AUTOSAR XML (schema 00050)
standard types defined: Boolean, Float
package /ARRoot
  swc implementation AntiPinchingSensorImpFile: programming-language=C, behavior=AntiPinchingSensorIB
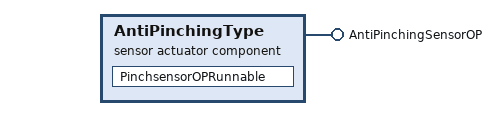
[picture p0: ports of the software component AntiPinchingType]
  sensor actuator sw component type AntiPinchingType
    provide port AntiPinchingSensorOP
    behavior AntiPinchingSensorIB
      runnable PinchsensorOPRunnable: external-triggering-point=AntiPinchingSensorOP.
  sender receiver interface PWControlSwitchSRIF: data-elements=variable-data-prototype=type=Boolean
  sender receiver interface PWMotorSRIF: data-elements=variable-data-prototype=type=Boolean
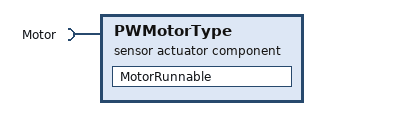
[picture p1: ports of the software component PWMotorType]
  sensor actuator sw component type PWMotorType
    require port Motor
    behavior MotorIB
      runnable MotorRunnable: variable-access=accessed-variable=/ARRoot/PWMotorSRIF/
  swc implementation PWMotorTypeImpFile: programming-language=C, behavior=MotorIB
  client server interface PositionSensingElementCSIF: client-server-operation=arguments=argument-data-prototype={type=Float, direction=OUT}
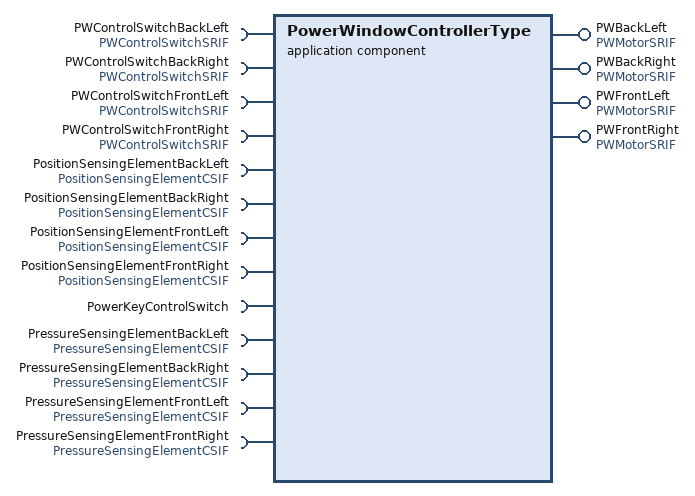
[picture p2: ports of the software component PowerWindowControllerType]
  application sw component type PowerWindowControllerType
    provide port PWBackLeft: provided-interface=PWMotorSRIF
    provide port PWBackRight: provided-interface=PWMotorSRIF
    4 x require port, all with required-interface=PWControlSwitchSRIF:
      PWControlSwitchBackLeft
      PWControlSwitchBackRight
      PWControlSwitchFrontLeft
      PWControlSwitchFrontRight
    provide port PWFrontLeft: provided-interface=PWMotorSRIF
    provide port PWFrontRight: provided-interface=PWMotorSRIF
    9 x require port:
      PositionSensingElementBackLeft: required-interface=PositionSensingElementCSIF
      PositionSensingElementBackRight: required-interface=PositionSensingElementCSIF
      PositionSensingElementFrontLeft: required-interface=PositionSensingElementCSIF
      PositionSensingElementFrontRight: required-interface=PositionSensingElementCSIF
      PowerKeyControlSwitch
      PressureSensingElementBackLeft: required-interface=PressureSensingElementCSIF
      PressureSensingElementBackRight: required-interface=PressureSensingElementCSIF
      PressureSensingElementFrontLeft: required-interface=PressureSensingElementCSIF
      PressureSensingElementFrontRight: required-interface=PressureSensingElementCSIF
    behavior PowerWindowIB
      16 x runnable:
        ActuatorBLRunnable: variable-access=accessed-variable=/ARRoot/PWMotorSRIF/
        ActuatorBRRunnable: variable-access=accessed-variable=/ARRoot/PWMotorSRIF/
        ActuatorFLRunnable: variable-access=accessed-variable=/ARRoot/PWMotorSRIF/
        ActuatorFRRunnable: variable-access=accessed-variable=/ARRoot/PWMotorSRIF/
        PositionSensingElementBLRunnable: synchronous-server-call-point=PositionSensingElementBackLeft.
        PositionSensingElementBRRunnable: synchronous-server-call-point=PositionSensingElementBackRight.
        PositionSensingElementFLRunnable: synchronous-server-call-point=PositionSensingElementFrontLeft.
        PositionSensingElementFRRunnable: synchronous-server-call-point=PositionSensingElementFrontRight.
        PressureSensingElementBLRunnable: synchronous-server-call-point=PressureSensingElementBackLeft.
        PressureSensingElementBRRunnable: synchronous-server-call-point=PressureSensingElementBackRight.
        PressureSensingElementFLRunnable: synchronous-server-call-point=PressureSensingElementFrontLeft.
        PressureSensingElementFRRunnable: synchronous-server-call-point=PressureSensingElementFrontRight.
        WindowControlSwitchBLRunnable: variable-access=accessed-variable=/ARRoot/PWControlSwitchSRIF/
        WindowControlSwitchBRRunnable: variable-access=accessed-variable=/ARRoot/PWControlSwitchSRIF/
        WindowControlSwitchFLRunnable: variable-access=accessed-variable=/ARRoot/PWControlSwitchSRIF/
        WindowControlSwitchFRRunnable: variable-access=accessed-variable=/ARRoot/PWControlSwitchSRIF/
  swc implementation PowerWindowImpFile: programming-language=C, behavior=PowerWindowIB
  client server interface PressureSensingElementCSIF: client-server-operation=arguments=argument-data-prototype={type=Float, direction=OUT}
  swc implementation ReedSensorImpFile: programming-language=C, behavior=ReedSensorIB
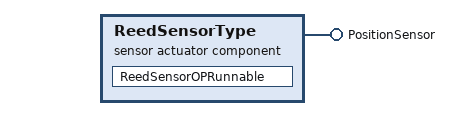
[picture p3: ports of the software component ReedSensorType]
  sensor actuator sw component type ReedSensorType
    provide port PositionSensor
    behavior ReedSensorIB
      runnable ReedSensorOPRunnable: external-triggering-point=PositionSensor.
